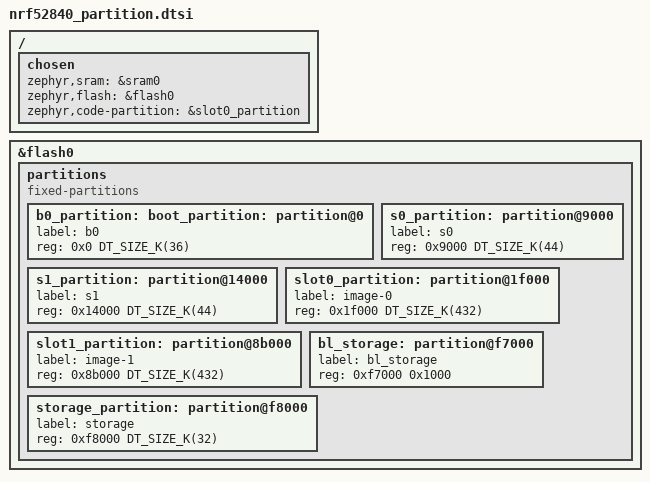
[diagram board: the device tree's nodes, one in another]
/*
 * Copyright (c) 2024 Jacob Winther
 *
 * SPDX-License-Identifier: Apache-2.0
 */

/ {
	chosen {
		zephyr,sram = &sram0;
		zephyr,flash = &flash0;
		zephyr,code-partition = &slot0_partition;
	};
};

&flash0 {
	partitions {
		compatible = "fixed-partitions";
		#address-cells = <1>;
		#size-cells = <1>;

		b0_partition: boot_partition: partition@0 {
			label = "b0";
			reg = <0x0 DT_SIZE_K(36)>;
		};

		s0_partition: partition@9000 {
			label = "s0";
			reg = <0x9000 DT_SIZE_K(44)>;
		};

		s1_partition: partition@14000 {
			label = "s1";
			reg = <0x14000 DT_SIZE_K(44)>;
		};

		slot0_partition: partition@1f000 {
			label = "image-0";
			reg = <0x1f000 DT_SIZE_K(432)>;
		};

		slot1_partition: partition@8b000 {
			label = "image-1";
			reg = <0x8b000 DT_SIZE_K(432)>;
		};

		bl_storage: partition@f7000 {
			label = "bl_storage";
			reg = <0xf7000 0x1000>;
		};

		storage_partition: partition@f8000 {
			label = "storage";
			reg = <0xf8000 DT_SIZE_K(32)>;
		};
	};
};
